# WS63 register map
File version: 1.0
CPU: other r0p0, little endian, MPU, FPU, 3 interrupt priority bits
Registers are 32-bit, read-write, reset 0x0 unless marked. A register's access mark holds for its fields unless they carry their own. Offsets are from the block's base; [hi:lo] are bit positions.

## I2S — I2S/SIO synchronous audio interface (v151)
Base 0x44025000
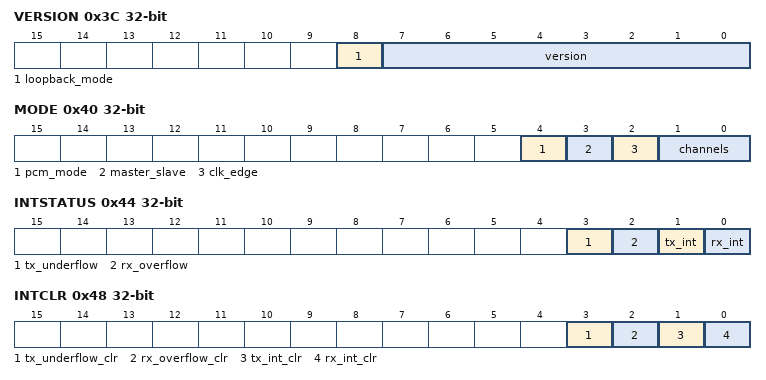
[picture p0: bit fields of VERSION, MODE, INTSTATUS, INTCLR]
0x3C VERSION — Version and loopback register
  [8] loopback_mode — Loopback mode enable
  [7:0] version ro — IP version
0x40 MODE — I2S/PCM mode register
  [4] pcm_mode — PCM mode: 0=I2S; 1=PCM
  [3] master_slave — Mode: 0=slave; 1=master
  [2] clk_edge — Clock edge: 0=rising; 1=falling
  [1:0] channels — Number of channels: 0=2ch; 1=4ch; 2=6ch; 3=8ch
0x44 INTSTATUS — Interrupt status register
  [3] tx_underflow ro — TX underflow status
  [2] rx_overflow ro — RX overflow status
  [1] tx_int ro — TX interrupt status
  [0] rx_int ro — RX interrupt status
0x48 INTCLR — Interrupt clear register
  [3] tx_underflow_clr wo — Clear TX underflow
  [2] rx_overflow_clr wo — Clear RX overflow
  [1] tx_int_clr wo — Clear TX interrupt
  [0] rx_int_clr wo — Clear RX interrupt
0x4C LEFT_TX — TX left channel data
  [31:0] left_tx_data
0x50 RIGHT_TX — TX right channel data
  [31:0] right_tx_data
0x54 LEFT_RX — RX left channel data
  [31:0] left_rx_data ro
0x58 RIGHT_RX — RX right channel data
  [31:0] right_rx_data ro
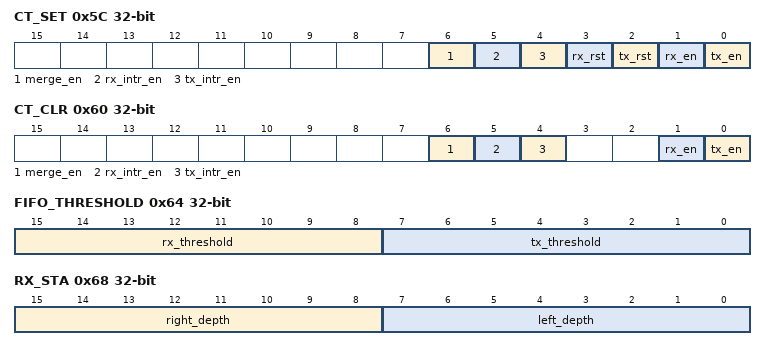
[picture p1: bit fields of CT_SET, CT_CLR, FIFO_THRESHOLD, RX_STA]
0x5C CT_SET — Control set register
  [6] merge_en wo — Merge enable set
  [5] rx_intr_en wo — RX interrupt enable set
  [4] tx_intr_en wo — TX interrupt enable set
  [3] rx_rst wo — RX reset set
  [2] tx_rst wo — TX reset set
  [1] rx_en wo — RX enable set
  [0] tx_en wo — TX enable set
0x60 CT_CLR — Control clear register
  [6] merge_en wo — Merge disable
  [5] rx_intr_en wo — RX interrupt disable
  [4] tx_intr_en wo — TX interrupt disable
  [1] rx_en wo — RX enable clear
  [0] tx_en wo — TX enable clear
0x64 FIFO_THRESHOLD
  [15:8] rx_threshold — RX FIFO threshold
  [7:0] tx_threshold — TX FIFO threshold
0x68 RX_STA — RX status register
  [15:8] right_depth ro — RX right FIFO depth
  [7:0] left_depth ro — RX left FIFO depth
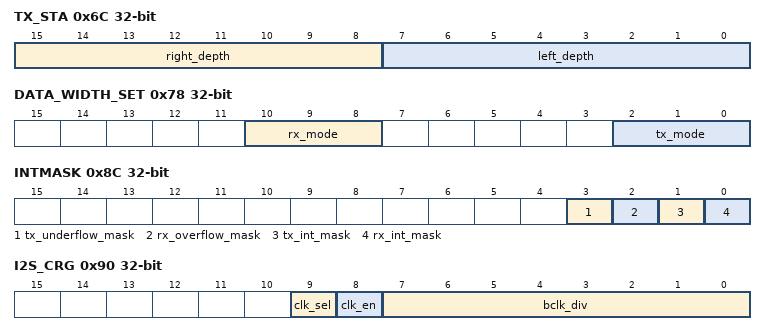
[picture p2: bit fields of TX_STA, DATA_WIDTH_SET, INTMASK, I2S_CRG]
0x6C TX_STA — TX status register
  [15:8] right_depth ro — TX right FIFO depth
  [7:0] left_depth ro — TX left FIFO depth
0x78 DATA_WIDTH_SET — Data width register
  [10:8] rx_mode — RX data width mode
  [2:0] tx_mode — TX data width mode
0x84 SIGNED_EXT — Signed extension enable
  [0] signed_ext_en
0x8C INTMASK — Interrupt mask register
  [3] tx_underflow_mask
  [2] rx_overflow_mask
  [1] tx_int_mask — TX interrupt mask
  [0] rx_int_mask — RX interrupt mask
0x90 I2S_CRG — I2S clock/reset generator
  [9] clk_sel — Clock source select
  [8] clk_en — Clock enable
  [7:0] bclk_div — BCLK divider
0x94 I2S_BCLK_DIV_NUM — BCLK divider number
  [6:0] bclk_div_num
0x98 I2S_FS_DIV_NUM — FS divider number
  [9:0] fs_div_num
0x9C I2S_FS_DIV_RATIO_NUM — FS divider ratio number
  [10:0] fs_div_ratio_num

## LSADC — Low-speed ADC controller (12-bit SAR, 6 channels, v154)
Base 0x4400C000
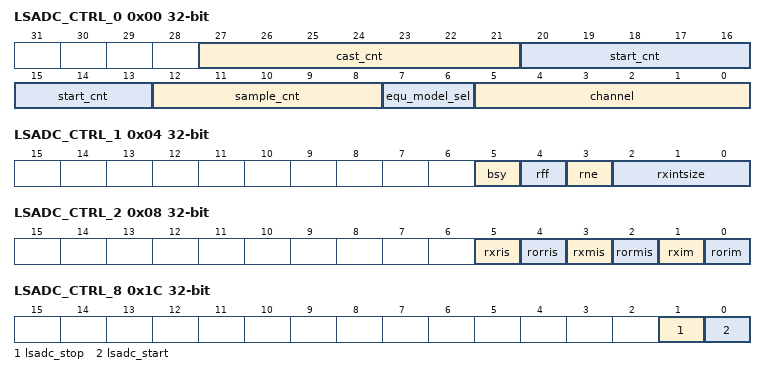
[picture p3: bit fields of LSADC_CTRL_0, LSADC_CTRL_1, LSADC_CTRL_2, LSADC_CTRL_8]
0x00 LSADC_CTRL_0 — Scan config (adc_ctrl_data): per-channel enable + sample timing. Set via hal_adc_auto_scan_mode_set.
  [27:21] cast_cnt — Cast count (7-bit)
  [20:13] start_cnt — Start count (8-bit; SDK field name satrt_cnt)
  [12:8] sample_cnt — Sample count (5-bit)
  [7:6] equ_model_sel — Averaging mode: 0=1x, 1=2x, 2=4x, 3=8x samples
  [5:0] channel — Per-channel enable bitmask (bit n enables channel n, 0-5)
0x04 LSADC_CTRL_1 — FIFO status + interrupt waterline (adc_fifo_data)
  [5] bsy ro — ADC busy
  [4] rff ro — RX FIFO full
  [3] rne ro — RX FIFO not empty
  [2:0] rxintsize — RX FIFO interrupt waterline (3-bit)
0x08 LSADC_CTRL_2 — Interrupt mask/status (adc_irg_data)
  [5] rxris ro — RX FIFO raw interrupt status
  [4] rorris ro — RX overflow raw interrupt status
  [3] rxmis ro — RX FIFO masked interrupt status
  [2] rormis ro — RX overflow masked interrupt status
  [1] rxim — RX FIFO interrupt mask
  [0] rorim — RX overflow interrupt mask
0x0C LSADC_CTRL_3 — ADC control register 3 (analog, reserved)
  [31:0] val — Raw register value
0x10 LSADC_CTRL_4 — ADC control register 4 (analog, reserved)
  [31:0] val — Raw register value
0x14 LSADC_CTRL_6 — ADC control register 6 (analog, reserved)
  [31:0] val — Raw register value
0x18 LSADC_CTRL_7 — ADC control register 7 (analog, reserved)
  [31:0] val — Raw register value
0x1C LSADC_CTRL_8 — Scan start/stop (adc_scan_start_and_stop_data)
  [1] lsadc_stop — Write 1 to stop a scan
  [0] lsadc_start — Write 1 to start a scan
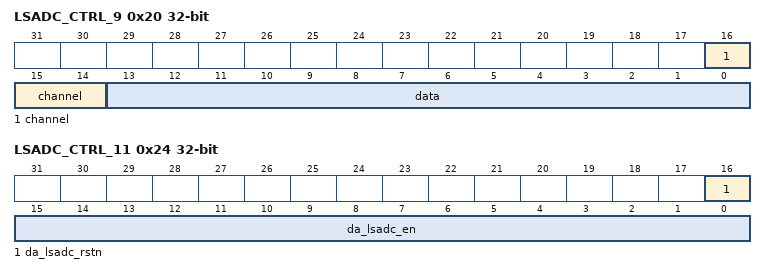
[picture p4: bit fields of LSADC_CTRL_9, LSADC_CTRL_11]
0x20 LSADC_CTRL_9 — FIFO read data (adc_fifo_read_data): 14-bit code + 3-bit channel
  [16:14] channel ro — Source channel (0-5)
  [13:0] data ro — 14-bit conversion code
0x24 LSADC_CTRL_11 — Analog enable/reset (adc_enable_data)
  [16] da_lsadc_rstn — Analog reset, active low: 1=release reset
  [15:0] da_lsadc_en — Analog block enable bits (16-bit; SDK ORs 0x7000/0xE7F/0x100/0x80 during power-up)
0x28 LSADC_CTRL_12 — ADC control register 12 (analog, reserved)
  [31:0] val — Raw register value
0xDC CFG_DATA_SEL — Data output select (base+0xDC)
  [0] data_sel — 0=raw ADC data, 1=post-processed
0xE0 CFG_OFFSET — Offset correction (base+0xE0)
  [15:0] offset — ADC offset correction
0xE4 CFG_GAIN — Gain correction (base+0xE4)
  [15:0] gain — ADC gain correction
0xE8 CFG_CIC_FILTER_EN — CIC filter enable (base+0xE8)
  [0] cic_filter_en — CIC filter enable
0xEC CFG_CIC_OSR — CIC oversampling ratio (base+0xEC)
  [7:0] cic_osr — CIC oversampling ratio
